# TC37X register map
File version: 1.0.0
CPU: CM4 r0p1, little endian, MPU, FPU, VTOR, 3 interrupt priority bits
Registers are 16-bit, read-write, reset 0x0 unless marked. A register's access mark holds for its fields unless they carry their own. Offsets are from the block's base; [hi:lo] are bit positions; lines under a group give offsets from that group; {n}, {i} and the like mark numbered series.

## PMS — ce_pms
Base 0xF0248000
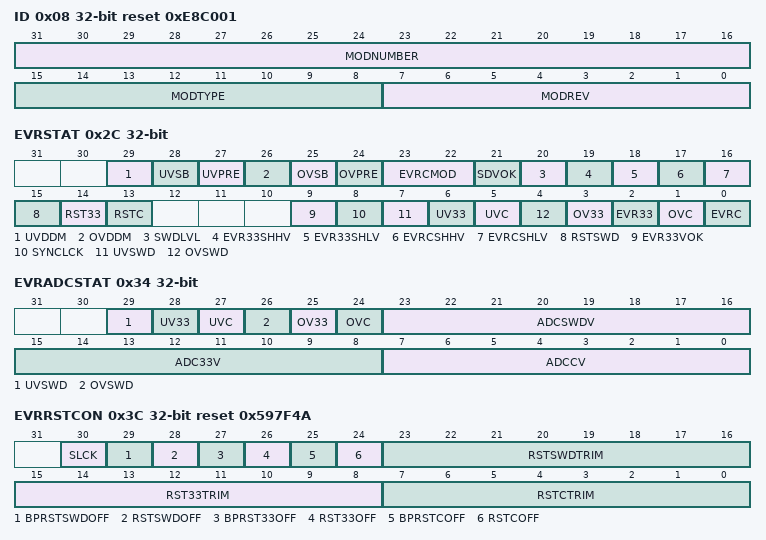
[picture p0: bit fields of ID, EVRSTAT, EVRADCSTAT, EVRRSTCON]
0x08 ID 32-bit ro reset 0xE8C001 — Identification Register
  [31:16] MODNUMBER — Module Number - MODNUMBER
  [15:8] MODTYPE — Module Type - MODTYPE
  [7:0] MODREV — Module Revision Number - MODREV
0x2C EVRSTAT 32-bit ro — EVR Status Register
  [29] UVDDM — ADC VDDM Supply Under-voltage event flag - UVDDM
  [28] UVSB — Standby Supply or VEVRSB Under-voltage event flag - UVSB
  [27] UVPRE — Pre Regulator VDDPD Under-voltage event flag - UVPRE
  [26] OVDDM — ADC VDDM Supply Over-voltage event flag - OVDDM
  [25] OVSB — Standby Supply or VEVRSB Over-voltage event flag - OVSB
  [24] OVPRE — Pre Regulator VDDPD Over-voltage event flag - OVPRE
  [23:22] EVRCMOD — EVRC Mode - EVRCMOD
  [21] SDVOK — EVRC Regulator Voltage OK status - SDVOK
  [20] SWDLVL — VEXT External Supply Level Status - SWDLVL
  [19] EVR33SHHV — Short to supply - EVR33SHHV
  [18] EVR33SHLV — Short to ground - EVR33SHLV
  [17] EVRCSHHV — Short to supply - EVRCSHHV
  [16] EVRCSHLV — Short to ground - EVRCSHLV
  [15] RSTSWD — EVR SWD Reset Trigger - RSTSWD
  [14] RST33 — EVR33 Reset Trigger - RST33
  [13] RSTC — EVRC Reset Trigger - RSTC
  [9] EVR33VOK — EVR33 Regulator Voltage OK status - EVR33VOK
  [8] SYNCLCK — EVRC Synchronization Input Locked status(sd_sync_in_locked_o) - SYNCLCK
  [7] UVSWD — VEXT Under-voltage event flag - UVSWD
  [6] UV33 — VDDP3 Under-voltage event flag - UV33
  [5] UVC — VDD Under-voltage event flag - UVC
  [4] OVSWD — VEXT Over-voltage event flag - OVSWD
  [3] OV33 — VDDP3 Over-voltage event flag - OV33
  [2] EVR33 — EVR33 status - EVR33
  [1] OVC — VDD Over-voltage event flag - OVC
  [0] EVRC — EVRC status - EVRC
0x34 EVRADCSTAT 32-bit ro — EVR Primary ADC Status Register
  [29] UVSWD — Supply Watchdog (SWD) or VEXT Under-voltage event flag - UVSWD
  [28] UV33 — EVR33 Regulator or VDDP3 Under-voltage event flag - UV33
  [27] UVC — EVRC Regulator or VDD Under-voltage event flag - UVC
  [26] OVSWD — Supply Watchdog (SWD) or VEXT Over-voltage event flag - OVSWD
  [25] OV33 — EVR33 Regulator or VDDP3 Over-voltage event flag - OV33
  [24] OVC — EVRC Regulator or VDD Over-voltage event flag - OVC
  [23:16] ADCSWDV — ADC VEXT Supply Conversion Result - ADCSWDV
  [15:8] ADC33V — ADC VDDP3 Voltage Conversion Result - ADC33V
  [7:0] ADCCV — ADC VDD Core Voltage Conversion Result - ADCCV
0x3C EVRRSTCON 32-bit reset 0x597F4A — EVR Reset Control Register
  [30] SLCK — HSM Security Lock - SLCK
  [29] BPRSTSWDOFF wo — Bit Protection RSTSWDOFF - BPRSTSWDOFF
  [28] RSTSWDOFF — VEXT Reset Enable - RSTSWDOFF
  [27] BPRST33OFF wo — Bit Protection RST33OFF - BPRST33OFF
  [26] RST33OFF — VDDP3 Reset Enable - RST33OFF
  [25] BPRSTCOFF wo — Bit Protection RSTCOFF - BPRSTCOFF
  [24] RSTCOFF — VDD Reset Enable - RSTCOFF
  [23:16] RSTSWDTRIM — VEXT Supply Reset Trim Value - RSTSWDTRIM
  [15:8] RST33TRIM — VDDP3 Supply Reset Trim Value - RST33TRIM
  [7:0] RSTCTRIM — VDD Supply Reset Trim Value - RSTCTRIM
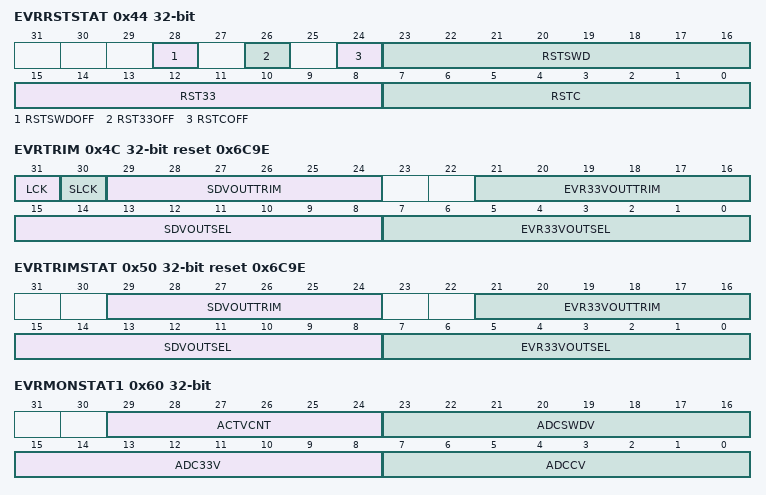
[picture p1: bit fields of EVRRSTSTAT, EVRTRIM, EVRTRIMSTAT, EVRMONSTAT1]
0x44 EVRRSTSTAT 32-bit ro — EVR Reset Status Register
  [28] RSTSWDOFF — EVR SWD Reset Enable - RSTSWDOFF
  [26] RST33OFF — EVR33 Reset Enable Status - RST33OFF
  [24] RSTCOFF — EVRC Reset Enable Status - RSTCOFF
  [23:16] RSTSWD — VEXT Supply Reset Value Status - RSTSWD
  [15:8] RST33 — VDDP3 Supply Reset Value Status - RST33
  [7:0] RSTC — VDD Supply Reset Value Status - RSTC
0x4C EVRTRIM 32-bit reset 0x6C9E — EVR Trim Control Register
  [31] LCK ro — Lock Status - LCK
  [30] SLCK — HSM Security Lock - SLCK
  [29:24] SDVOUTTRIM — EVRC Regulator Output Voltage Trim Value(vtrim_trim_i) - SDVOUTTRIM
  [21:16] EVR33VOUTTRIM — EVR33 Regulator Output Voltage Trim Value - EVR33VOUTTRIM
  [15:8] SDVOUTSEL — EVRC Regulator Output Voltage Target Value - SDVOUTSEL
  [7:0] EVR33VOUTSEL — EVR33 Regulator Output Voltage Target Value - EVR33VOUTSEL
0x50 EVRTRIMSTAT 32-bit ro reset 0x6C9E — EVR Trim Status Register
  [29:24] SDVOUTTRIM — EVRC Regulator Output Voltage Trim Value(vtrim_trim_o) - SDVOUTTRIM
  [21:16] EVR33VOUTTRIM — EVR33 Regulator Output Voltage Trim Value - EVR33VOUTTRIM
  [15:8] SDVOUTSEL — EVRC Regulator Output Voltage Target Value - SDVOUTSEL
  [7:0] EVR33VOUTSEL — EVR33 Regulator Output Voltage Target Value - EVR33VOUTSEL
0x60 EVRMONSTAT1 32-bit ro — EVR Secondary ADC Status Register 1
  [29:24] ACTVCNT — Secondary Monitor Activity Counter - ACTVCNT
  [23:16] ADCSWDV — VEXT Supply Secondary ADC Conversion Result - ADCSWDV
  [15:8] ADC33V — VDDP3 Supply Secondary ADC Conversion Result - ADC33V
  [7:0] ADCCV — VDD Supply Secondary ADC Conversion Result - ADCCV
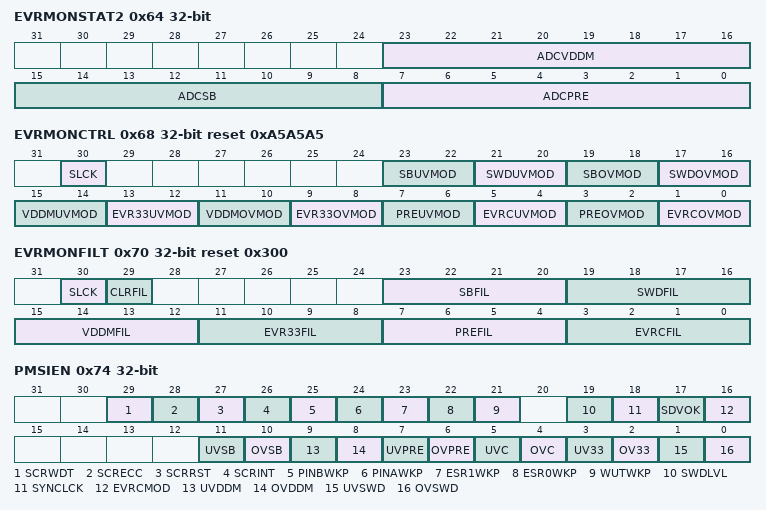
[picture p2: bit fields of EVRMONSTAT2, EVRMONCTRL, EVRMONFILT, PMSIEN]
0x64 EVRMONSTAT2 32-bit ro — EVR Secondary ADC Status Register 2
  [23:16] ADCVDDM — VDDM Supply Secondary ADC Conversion Result - ADCVDDM
  [15:8] ADCSB — VEVRSB Supply Secondary ADC Conversion Result - ADCSB
  [7:0] ADCPRE — VDDPD Supply Secondary ADC Conversion Result - ADCPRE
0x68 EVRMONCTRL 32-bit reset 0xA5A5A5 — EVR Secondary Monitor Control Register
  [30] SLCK — HSM Security Lock - SLCK
  [23:22] SBUVMOD — EVR Standby Supply or VEVRSB Under-voltage monitoring mode - SBUVMOD
  [21:20] SWDUVMOD — VEXT Under-voltage monitoring mode - SWDUVMOD
  [19:18] SBOVMOD — EVR Standby Supply or VEVRSB Over-voltage monitoring mode - SBOVMOD
  [17:16] SWDOVMOD — VEXT Over-voltage monitoring mode - SWDOVMOD
  [15:14] VDDMUVMOD — VDDM ADC Supply Under-voltage monitoring mode - VDDMUVMOD
  [13:12] EVR33UVMOD — VDDP3 Supply Under-voltage monitoring mode - EVR33UVMOD
  [11:10] VDDMOVMOD — VDDM ADC Supply Over-voltage monitoring mode - VDDMOVMOD
  [9:8] EVR33OVMOD — VDDP3 Supply Over-voltage monitoring mode - EVR33OVMOD
  [7:6] PREUVMOD — EVRPR or VDDPD Under-voltage monitoring mode - PREUVMOD
  [5:4] EVRCUVMOD — VDD Under-voltage monitoring mode - EVRCUVMOD
  [3:2] PREOVMOD — EVRPR or VDDPD Over-voltage monitoring mode - PREOVMOD
  [1:0] EVRCOVMOD — VDD Over-voltage monitoring mode - EVRCOVMOD
0x70 EVRMONFILT 32-bit reset 0x300 — EVR Secondary Monitor Filter Register
  [30] SLCK — HSM Security Lock - SLCK
  [29] CLRFIL — Clear all Spike Filters - CLRFIL
  [23:20] SBFIL — VEVRSB Secondary ADC Supply Filter - SBFIL
  [19:16] SWDFIL — VEXT Secondary ADC Supply Filter - SWDFIL
  [15:12] VDDMFIL — VDDM Secondary ADC Supply Filter - VDDMFIL
  [11:8] EVR33FIL — VDDP3 Secondary ADC Supply Filter - EVR33FIL
  [7:4] PREFIL — VDDPD Secondary ADC Supply Filter - PREFIL
  [3:0] EVRCFIL — VDD Secondary ADC Supply Filter - EVRCFIL
0x74 PMSIEN 32-bit — PMS Interrupt Enable Register
  [29] SCRWDT — SCRWDT Interrupt enable - SCRWDT
  [28] SCRECC — SCRECC Interrupt enable - SCRECC
  [27] SCRRST — SCRRST Interrupt enable - SCRRST
  [26] SCRINT — SCRINT Interrupt enable - SCRINT
  [25] PINBWKP — PINBWKP Interrupt enable - PINBWKP
  [24] PINAWKP — PINAWKP Interrupt enable - PINAWKP
  [23] ESR1WKP — ESR1WKP Interrupt enable - ESR1WKP
  [22] ESR0WKP — ESR0WKP Interrupt enable - ESR0WKP
  [21] WUTWKP — WUTWKP Interrupt enable - WUTWKP
  [19] SWDLVL — SWDLVL Interrupt enable - SWDLVL
  [18] SYNCLCK — SD SYNCLCK Interrupt enable - SYNCLCK
  [17] SDVOK — SDVOK Interrupt enable - SDVOK
  [16] EVRCMOD — EVRCMOD Interrupt enable - EVRCMOD
  [11] UVSB — UVSB Interrupt enable - UVSB
  [10] OVSB — OVSB Interrupt enable - OVSB
  [9] UVDDM — UVDDM Interrupt enable - UVDDM
  [8] OVDDM — OVDDM Interrupt enable - OVDDM
  [7] UVPRE — UVPRE Interrupt enable - UVPRE
  [6] OVPRE — OVPRE Interrupt enable - OVPRE
  [5] UVC — UVC Interrupt enable - UVC
  [4] OVC — OVC Interrupt enable - OVC
  [3] UV33 — UV33 Interrupt enable - UV33
  [2] OV33 — OV33 Interrupt enable - OV33
  [1] UVSWD — UVSWD Interrupt enable - UVSWD
  [0] OVSWD — OVSWD Interrupt enable - OVSWD
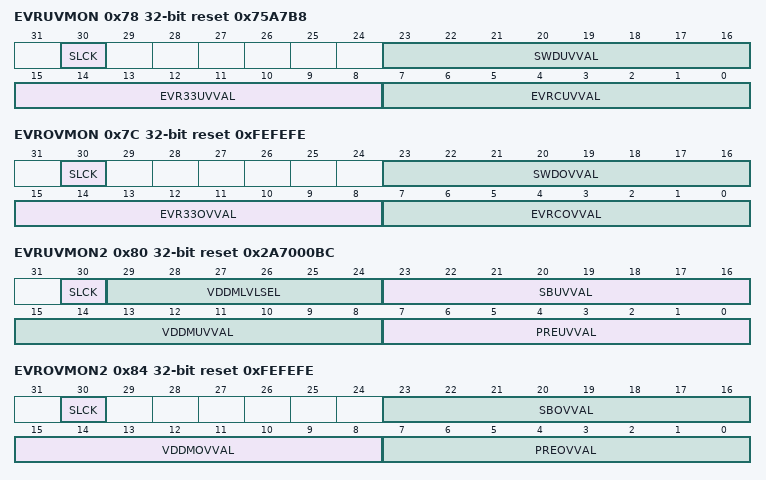
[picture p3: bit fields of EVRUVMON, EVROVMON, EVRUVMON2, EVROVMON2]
0x78 EVRUVMON 32-bit reset 0x75A7B8 — EVR Secondary Under-voltage Monitor Register
  [30] SLCK — HSM Security Lock - SLCK
  [23:16] SWDUVVAL — VEXT Supply Secondary Monitor Under-voltage threshold - SWDUVVAL
  [15:8] EVR33UVVAL — VDDP3 Supply Secondary Monitor Under-voltage threshold - EVR33UVVAL
  [7:0] EVRCUVVAL — VDD Supply Secondary Monitor Under-voltage threshold - EVRCUVVAL
0x7C EVROVMON 32-bit reset 0xFEFEFE — EVR Secondary Over-voltage Monitor Register
  [30] SLCK — HSM Security Lock - SLCK
  [23:16] SWDOVVAL — VEXT Supply Secondary Monitor Over-voltage threshold - SWDOVVAL
  [15:8] EVR33OVVAL — VDDP3 Supply Secondary Monitor Over-voltage threshold - EVR33OVVAL
  [7:0] EVRCOVVAL — VDD Supply Secondary Monitor Over-voltage threshold - EVRCOVVAL
0x80 EVRUVMON2 32-bit reset 0x2A7000BC — EVR Secondary Under-voltage Monitor Register 2
  [30] SLCK — HSM Security Lock - SLCK
  [29:24] VDDMLVLSEL — VDDM Level Select - VDDMLVLSEL
  [23:16] SBUVVAL — VEVRSB Supply Secondary Monitor Under-voltage threshold - SBUVVAL
  [15:8] VDDMUVVAL — VDDM Supply Secondary Monitor Under-voltage threshold - VDDMUVVAL
  [7:0] PREUVVAL — VDDPD Supply Secondary Monitor Under-voltage threshold - PREUVVAL
0x84 EVROVMON2 32-bit reset 0xFEFEFE — EVR Secondary Over-voltage Monitor Register 2
  [30] SLCK — HSM Security Lock - SLCK
  [23:16] SBOVVAL — VEVRSB Supply Secondary Monitor Over-voltage threshold - SBOVVAL
  [15:8] VDDMOVVAL — VDDM Supply Secondary Monitor Over-voltage threshold - VDDMOVVAL
  [7:0] PREOVVAL — VDDPD Supply Secondary Monitor Over-voltage threshold - PREOVVAL
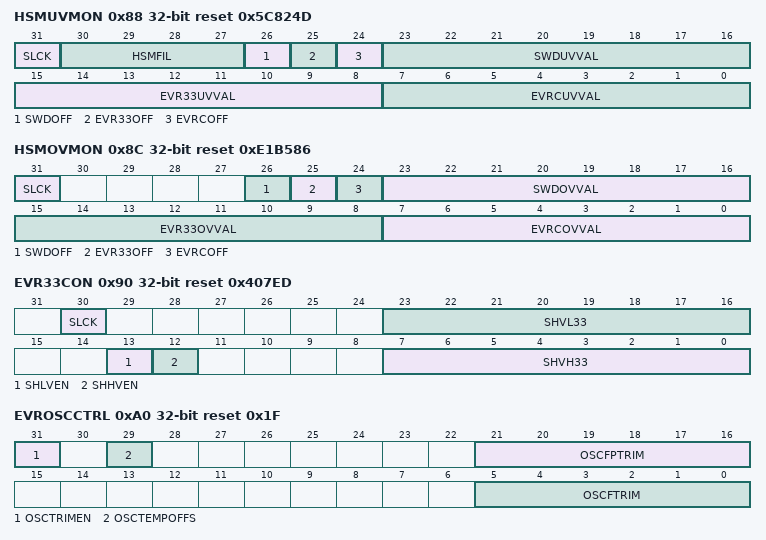
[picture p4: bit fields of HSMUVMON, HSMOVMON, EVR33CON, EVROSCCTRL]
0x88 HSMUVMON 32-bit reset 0x5C824D — EVR Primary HSM Under-voltage Monitor Register
  [31] SLCK — HSM Security Lock - SLCK
  [30:27] HSMFIL — HSM Voltage Filter - HSMFIL
  [26] SWDOFF — VEXT Primary Monitor UV Alarm Disable - SWDOFF
  [25] EVR33OFF — VDDP3 Primary Monitor UV Alarm Disable - EVR33OFF
  [24] EVRCOFF — VDD Primary Monitor UV Alarm Disable - EVRCOFF
  [23:16] SWDUVVAL — VEXT Supply Primary Monitor Alarm Under-voltage threshold - SWDUVVAL
  [15:8] EVR33UVVAL — VDDP3 Supply Primary Monitor Alarm Under-voltage threshold - EVR33UVVAL
  [7:0] EVRCUVVAL — VDD Supply Primary Monitor Alarm Under-voltage threshold - EVRCUVVAL
0x8C HSMOVMON 32-bit reset 0xE1B586 — EVR Primary HSM Over-voltage Monitor Register
  [31] SLCK — HSM Security Lock - SLCK
  [26] SWDOFF — VEXT Primary Monitor OV Alarm Disable - SWDOFF
  [25] EVR33OFF — VDDP3 Primary Monitor OV Alarm Disable - EVR33OFF
  [24] EVRCOFF — VDD Primary Monitor OV Alarm Disable - EVRCOFF
  [23:16] SWDOVVAL — VEXT Supply Primary Monitor Alarm Over-voltage threshold - SWDOVVAL
  [15:8] EVR33OVVAL — VDDP3 Supply Primary Monitor Alarm Over-voltage threshold - EVR33OVVAL
  [7:0] EVRCOVVAL — VDD Supply Primary Monitor Alarm Over-voltage threshold - EVRCOVVAL
0x90 EVR33CON 32-bit reset 0x407ED — EVR33 Control Register
  [30] SLCK — HSM Security Lock - SLCK
  [23:16] SHVL33 — Short to Ground Voltage Threshold(x_i) - SHVL33
  [13] SHLVEN — Short to Low Detection Enable - SHLVEN
  [12] SHHVEN — Short to High Detection Enable - SHHVEN
  [7:0] SHVH33 — Short to Supply Voltage Threshold(x_i) - SHVH33
0xA0 EVROSCCTRL 32-bit reset 0x1F — EVR Oscillator Control Register
  [31] OSCTRIMEN — Dynamic Oscillator Trim Enable - OSCTRIMEN
  [29] OSCTEMPOFFS — Oscillator Temperature Offset Coefficient - OSCTEMPOFFS
  [21:16] OSCFPTRIM — OSC Fine Trim Signed Value - OSCFPTRIM
  [5:0] OSCFTRIM — Back-up Clock Fine Trim Value - OSCFTRIM
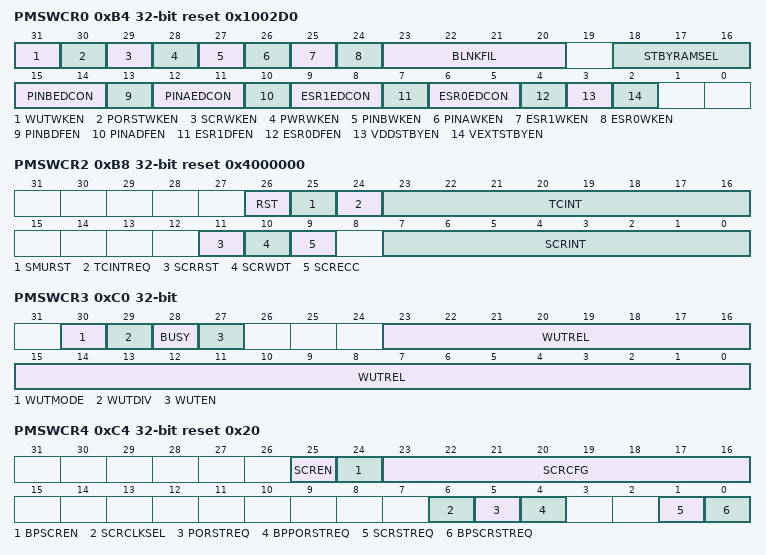
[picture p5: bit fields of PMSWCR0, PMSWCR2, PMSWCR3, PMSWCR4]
0xB4 PMSWCR0 32-bit reset 0x1002D0 — Standby and Wake-up Control Register 0
  [31] WUTWKEN — WUT Wake-up enable from Standby - WUTWKEN
  [30] PORSTWKEN — PORST pin Wake-up enable from Standby - PORSTWKEN
  [29] SCRWKEN — Standby Controller Wake-up enable from Standby - SCRWKEN
  [28] PWRWKEN — Standby Wake-up Enable on VEXT Supply ramp-up - PWRWKEN
  [27] PINBWKEN — Pin B Wake-up enable from Standby - PINBWKEN
  [26] PINAWKEN — Pin A Wake-up enable from Standby - PINAWKEN
  [25] ESR1WKEN — ESR1 Wake-up enable from Standby - ESR1WKEN
  [24] ESR0WKEN — ESR0 Wake-up enable from Standby - ESR0WKEN
  [23:20] BLNKFIL — Blanking Filter delay for Wake-up - BLNKFIL
  [18:16] STBYRAMSEL — Standby RAM supply in Standby Mode - STBYRAMSEL
  [15:14] PINBEDCON — PINB Edge Detection Control - PINBEDCON
  [13] PINBDFEN — PINB Digital Filter Enable - PINBDFEN
  [12:11] PINAEDCON — PINA Edge Detection Control - PINAEDCON
  [10] PINADFEN — PINA Digital Filter Enable - PINADFEN
  [9:8] ESR1EDCON — ESR1 Edge Detection Control - ESR1EDCON
  [7] ESR1DFEN — ESR1 Digital Filter Enable - ESR1DFEN
  [6:5] ESR0EDCON — ESR0 Edge Detection Control - ESR0EDCON
  [4] ESR0DFEN — ESR0 Digital Filter Enable - ESR0DFEN
  [3] VDDSTBYEN — Standby Entry on VDD Supply ramp-down - VDDSTBYEN
  [2] VEXTSTBYEN — Standby Entry on VEXT Supply ramp-down - VEXTSTBYEN
0xB8 PMSWCR2 32-bit reset 0x4000000 — Standby and Wake-up Control Register 2
  [26] RST ro — Application or System Reset indication flag - RST
  [25] SMURST ro — SMU Reset indication flag - SMURST
  [24] TCINTREQ — SW Interrupt request from PMS to Standby Controller. - TCINTREQ
  [23:16] TCINT — Data exchange from PMS main domain to Standby Controller. - TCINT
  [11] SCRRST — SCR Software reset flag - SCRRST
  [10] SCRWDT — SCR Watchdog Timer error / reset flag - SCRWDT
  [9] SCRECC — SCR RAM ECC error / reset flag - SCRECC
  [7:0] SCRINT ro — Data exchange from Standby Controller to PMS main domain. - SCRINT
0xC0 PMSWCR3 32-bit — Standby and Wake-up Control Register 3
  [30] WUTMODE — WUT mode selection - WUTMODE
  [29] WUTDIV — WUT clock divider - WUTDIV
  [28] BUSY ro — Lock Status - LCK
  [27] WUTEN — WUT enable - WUTEN
  [23:0] WUTREL — WUT reload value. - WUTREL
0xC4 PMSWCR4 32-bit reset 0x20 — Standby and Wake-up Control Register 4
  [25] SCREN — Standby Controller Enable request - SCREN
  [24] BPSCREN wo — Standby Controller Reset request enable - BPSCREN
  [23:16] SCRCFG — Hardware configuration of the 8 bit SCR controller. - SCRCFG
  [6] SCRCLKSEL — Default Clock selection on Standby Mode Entry - SCRCLKSEL
  [5] PORSTREQ — SCR Reset behavior on warm PORST in Normal RUN / SLEEP mode - PORSTREQ
  [4] BPPORSTREQ wo — Bit Protection for PORSTREQ - PORSTEN
  [1] SCRSTREQ — Standby Controller Reset request - SCRSTREQ
  [0] BPSCRSTREQ wo — Standby Controller Reset request enable - SCRSTEN
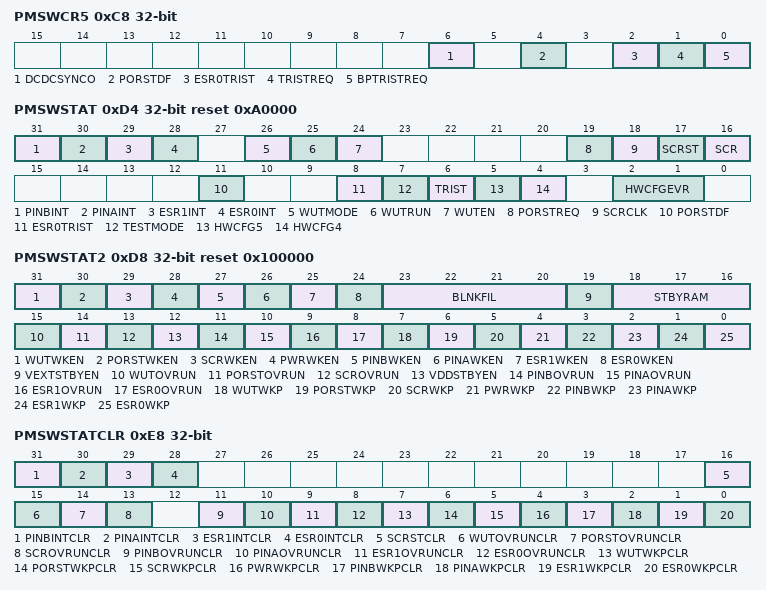
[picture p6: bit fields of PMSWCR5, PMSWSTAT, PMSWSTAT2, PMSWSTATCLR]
0xC8 PMSWCR5 32-bit — Standby and Wake-up Control Register 5
  [6] DCDCSYNCO — DC-DC Synchronisation Output
  [4] PORSTDF — PORST Digital Filter enable - PORSTDF
  [2] ESR0TRIST — ESR0 Tristate enable - ESR0TRIST
  [1] TRISTREQ — Tristate enable - TRISTREQ
  [0] BPTRISTREQ wo — Bit protection for Tristate request bit (TRISTREQ) - BPTRISTREQ
0xD4 PMSWSTAT 32-bit ro reset 0xA0000 — Standby and Wake-up Status Register
  [31] PINBINT — Pin B Interrupt flag - PINBINT
  [30] PINAINT — Pin A Interrupt flag - PINAINT
  [29] ESR1INT — ESR1 Interrupt flag - ESR1INT
  [28] ESR0INT — ESR0 Interrupt flag - ESR0INT
  [26] WUTMODE — WUT Mode status - WUTMODE
  [25] WUTRUN — WUT Run status - WUTRUN
  [24] WUTEN — WUT Enable status - WUTEN
  [19] PORSTREQ — Standby Controller Reset on warm PORST - PORSTREQ
  [18] SCRCLK — Current Clock configuration for SCR before Standby Mode Entry - SCRCLK
  [17] SCRST — Standby Controller Reset Indication flag - SCRST
  [16] SCR — Standby Controller status - SCR
  [11] PORSTDF — PORST Digital Filter status - PORSTDF
  [8] ESR0TRIST — ESR0 pin status during Standby - ESR0TRIST
  [7] TESTMODE — TESTMODE Pin status - TESTMODE
  [6] TRIST — Pad Tristate / Pull-up status - TRIST
  [5] HWCFG5 — Hardware Configuration Pin 5 status - HWCFG5
  [4] HWCFG4 — Hardware Configuration Pin 4 status - HWCFG4
  [2:1] HWCFGEVR — EVR Hardware Configuration status - HWCFGEVR
0xD8 PMSWSTAT2 32-bit ro reset 0x100000 — Standby and Wake-up Status Register 2
  [31] WUTWKEN — WUT Wake-up enable status - WUTWKEN
  [30] PORSTWKEN — PORST pin Wake-up enable status from Standby - PORSTWKEN
  [29] SCRWKEN — Standby Controller Wake-up Enable status - SCRWKEN
  [28] PWRWKEN — Standby Wake-up Enable status on VEXT Supply ramp-up - PWRWKEN
  [27] PINBWKEN — Pin B Wake-up enable status - PINBWKEN
  [26] PINAWKEN — Pin A Wake-up enable status - PINAWKEN
  [25] ESR1WKEN — ESR1 Wake-up enable status - ESR1WKEN
  [24] ESR0WKEN — ESR0 Wake-up enable status - ESR0WKEN
  [23:20] BLNKFIL — Blanking Filter Delay for VEXT Supply Wake-up - BLNKFIL
  [19] VEXTSTBYEN — Standby Entry Enable status on VEXT Supply ramp-down - VEXTSTBYWKEN
  [18:16] STBYRAM — Standby RAM Supply status - STBYRAM
  [15] WUTOVRUN — WUT Overrun status flag - WUTOVRUN
  [14] PORSTOVRUN — PORST Overrun status flag - PORSTOVRUN
  [13] SCROVRUN — SCR Overrun status flag - SCROVRUN
  [12] VDDSTBYEN — Standby Entry Enable status on VDD Supply ramp-down - VDDSTBYWKEN
  [11] PINBOVRUN — Pin B Overrun status flag - PINBOVRUN
  [10] PINAOVRUN — Pin A Overrun status flag - PINAOVRUN
  [9] ESR1OVRUN — ESR1 Overrun status flag - ESR1OVRUN
  [8] ESR0OVRUN — ESR0 Overrun status flag - ESR0OVRUN
  [7] WUTWKP — WUT Wake-up flag - WUTWKP
  [6] PORSTWKP — PORST Wake-up flag - PORSTWKP
  [5] SCRWKP — SCR Wake-up flag - SCRWKP
  [4] PWRWKP — Wake-up event on VEXT Supply ramp-up - PWRWKP
  [3] PINBWKP — Pin B Wake-up flag - PINBWKP
  [2] PINAWKP — Pin Wake-up flag - PINAWKP
  [1] ESR1WKP — ESR1 Wake-up flag - ESR1WKP
  [0] ESR0WKP — ESR0 Wake-up flag - ESR0WKP
0xDC PMSWUTCNT 32-bit ro — Standby WUT Counter Register
  [23:0] WUTCNT — WUT counter value. - WUTCNT
0xE8 PMSWSTATCLR 32-bit wo — Standby and Wake-up Status Clear Register
  [31] PINBINTCLR — PINB Interrupt indication flag clear - PINBINTCLR
  [30] PINAINTCLR — PINA Interrupt indication flag clear - PINAINTCLR
  [29] ESR1INTCLR — ESR1 Interrupt indication flag clear - ESR1INTCLR
  [28] ESR0INTCLR — ESR0 Interrupt indication flag clear - ESR0INTCLR
  [16] SCRSTCLR — Standby controller SCRST indication flag clear - SCRSTCLR
  [15] WUTOVRUNCLR — WUT Overrun status indication flag clear - WUTOVRUNCLR
  [14] PORSTOVRUNCLR — PORST Overrun status indication flag clear - PORSTOVRUNCLR
  [13] SCROVRUNCLR — SCR Overrun status indication flag clear - SCROVRUNCLR
  [11] PINBOVRUNCLR — PINB Overrun status indication flag clear - PINBOVRUNCLR
  [10] PINAOVRUNCLR — PINA Overrun status indication flag clear - PINAOVRUNCLR
  [9] ESR1OVRUNCLR — ESR1 Overrun status indication flag clear - ESR1OVRUNCLR
  [8] ESR0OVRUNCLR — ESR0 Overrun status indication flag clear - ESR0OVRUNCLR
  [7] WUTWKPCLR — WUT Wake-up indication flag clear - WUTWKPCLR
  [6] PORSTWKPCLR — PORST Wake-up indication flag clear - PORSTWKPCLR
  [5] SCRWKPCLR — SCR Wake-up indication flag clear - SCRWKPCLR
  [4] PWRWKPCLR — PWRWKP Wake-up indication flag clear - PWRWKPCLR
  [3] PINBWKPCLR — PINB Wake-up indication flag clear - PINBWKPCLR
  [2] PINAWKPCLR — PINA Wake-up indication flag clear - PINAWKPCLR
  [1] ESR1WKPCLR — ESR1 Wake-up indication flag clear - ESR1WKPCLR
  [0] ESR0WKPCLR — ESR0 Wake-up indication flag clear - ESR0WKPCLR
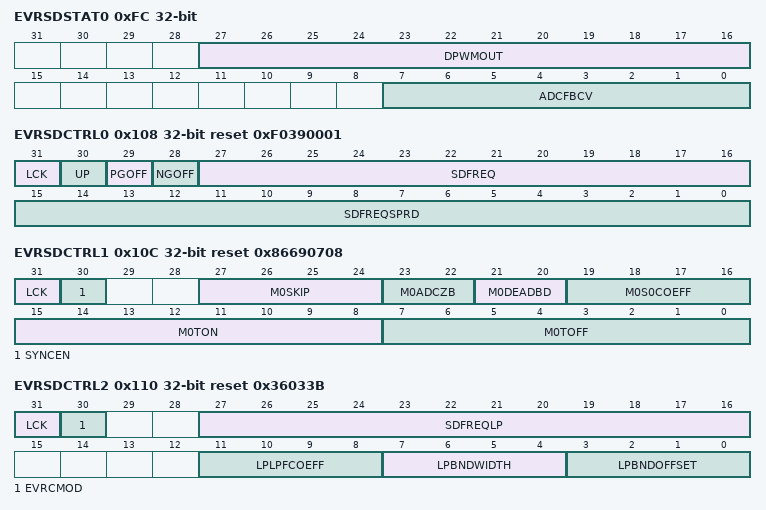
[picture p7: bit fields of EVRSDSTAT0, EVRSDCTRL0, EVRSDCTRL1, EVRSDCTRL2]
0xFC EVRSDSTAT0 32-bit ro — EVR SD Status Register 0
  [27:16] DPWMOUT — DPWM Control Output Status - DPWMOUT
  [7:0] ADCFBCV — Step Down Converter Core Voltage Feedback ADC Conversion Result - ADCFBCV
0x108 EVRSDCTRL0 32-bit reset 0xF0390001 — EVRC SD Control Register 0
  [31] LCK ro — Lock Status - LCK
  [30] UP — Update request for SMPS register values - UP
  [29] PGOFF — PMOS level during OFF state(drvslo_pgoff_i) - PGOFF
  [28] NGOFF — NMOS level during OFF state(drvslo_ngoff_i) - NGOFF
  [27:16] SDFREQ — Regulator Switching Frequency or Over-sampling Factor(m0osfl_fact_i+m0osfh_fact_i) - SDFREQ
  [15:0] SDFREQSPRD — Frequency Spread Threshold(freqsp_coeff_i) - SDFREQSPRD
0x10C EVRSDCTRL1 32-bit reset 0x86690708 — EVRC SD Control Register 1
  [31] LCK ro — Lock Status - LCK
  [30] SYNCEN — EVRC Synchronization input enable(synci0_en_i) - SYNCEN
  [27:24] M0SKIP — Skip Pulse Threshold(m0skip_thres_i) - M0SKIP
  [23:22] M0ADCZB — ADC Zero Bin(m0fcfg_adczb_i) - M0ADCZB
  [21:20] M0DEADBD — Dead Band(m0s0_deadbd_i) - M0DEADBD
  [19:16] M0S0COEFF — S0 coefficient(m0s0_coeff_i) - M0S0COEFF
  [15:8] M0TON — Minimum On Time(m0ton_minton_i) - M0TON
  [7:0] M0TOFF — Minimum Off Time(m0toff_mintof_i) - M0TOFF
0x110 EVRSDCTRL2 32-bit reset 0x36033B — EVRC SD Control Register 2
  [31] LCK ro — Lock Status - LCK
  [30] EVRCMOD — LPM or PWM EVRC Mode Activation - EVRCMOD
  [27:16] SDFREQLP — Regulator Over-sampling Factor(m1osfl_fact_i+m1osfh_fact_i) - SDFREQLP
  [11:8] LPLPFCOEFF — Low Pass Filter Coefficient(lplpf_coeff_i) - LPLPFCOEFF
  [7:4] LPBNDWIDTH — Low Power Mode Hysteresis Band Width(lpbnd_width_i) - LPBNDWIDTH
  [3:0] LPBNDOFFSET — Low Power Mode Hysteresis OFFSET(lpbnd_offset_i) - LPBNDOFFSET
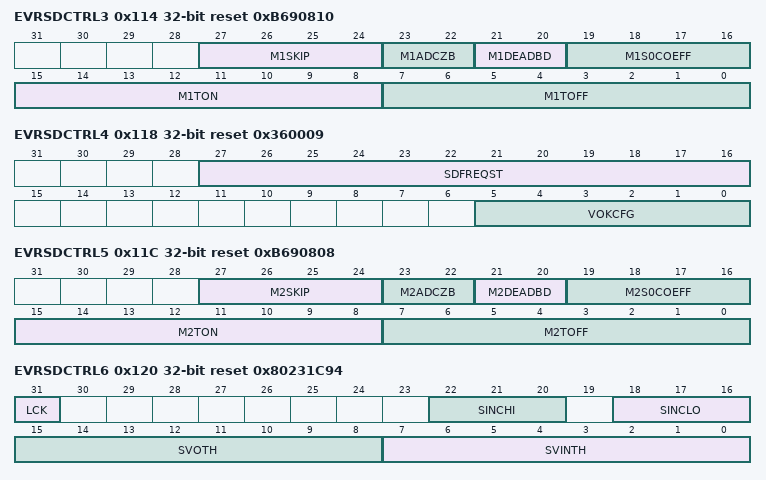
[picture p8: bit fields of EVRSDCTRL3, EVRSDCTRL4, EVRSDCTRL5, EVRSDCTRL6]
0x114 EVRSDCTRL3 32-bit reset 0xB690810 — EVRC SD Control Register 3
  [27:24] M1SKIP — Skip Pulse Threshold(m1skip_thres_i) - M1SKIP
  [23:22] M1ADCZB — ADC Zero Bin(m1fcfg_adczb_i) - M1ADCZB
  [21:20] M1DEADBD — Dead Band(m1s0_deadbd_i) - M1DEADBD
  [19:16] M1S0COEFF — S0 coefficient(m1s0_coeff_i) - M1S0COEFF
  [15:8] M1TON — Minimum On Time(m1ton_minton_i) - M1TON
  [7:0] M1TOFF — Minimum Off Time(m1toff_mintof_i) - M1TOFF
0x118 EVRSDCTRL4 32-bit reset 0x360009 — EVRC SD Control Register 4
  [27:16] SDFREQST — Regulator Switching Frequency or Over-sampling Factor(m2osfl_fact_i+m2osfh_fact_i) - SDFREQST
  [5:0] VOKCFG — Voltage OK Circuit Configuration(vokcfg_config_i) - VOKCFG
0x11C EVRSDCTRL5 32-bit reset 0xB690808 — EVRC SD Control Register 5
  [27:24] M2SKIP — Skip Pulse Threshold(m2skip_thres_i) - M2SKIP
  [23:22] M2ADCZB — ADC Zero Bin(m2fcfg_adczb_i) - M2ADCZB
  [21:20] M2DEADBD — Dead Band(m2s0_deadbd_i) - M2DEADBD
  [19:16] M2S0COEFF — S0 coefficient(m2s0_coeff_i) - M2S0COEFF
  [15:8] M2TON — Minimum On Time(m2ton_minton_i) - M2TON
  [7:0] M2TOFF — Minimum Off Time(m2toff_mintof_i) - M2TOFF
0x120 EVRSDCTRL6 32-bit reset 0x80231C94 — EVRC SD Control Register 6
  [31] LCK ro — Lock Status - LCK
  [22:20] SINCHI — Increment for high input voltage.(sinc_sinchi_i) - SINCHI
  [18:16] SINCLO — Increment for low input voltage.(sinc_sinclo_i) - SINCLO
  [15:8] SVOTH — Vout threshold to switch from open loop start-up to closed loop mode.(svoth_thres_i) - SVOTH
  [7:0] SVINTH — Vin threshold to switch between SINCLO or SINCHI.(svinth_thres_i) - SVINTH
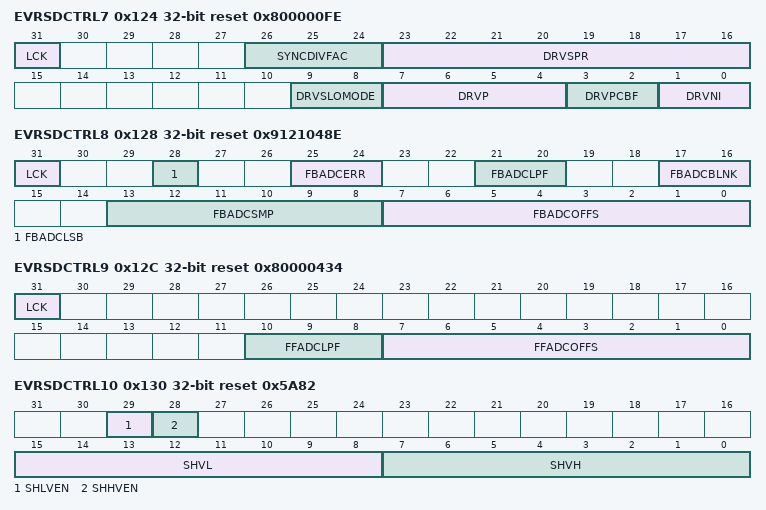
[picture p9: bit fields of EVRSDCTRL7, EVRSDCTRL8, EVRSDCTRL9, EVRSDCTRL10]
0x124 EVRSDCTRL7 32-bit reset 0x800000FE — EVRC SD Control Register 7
  [31] LCK ro — Lock Status - LCK
  [26:24] SYNCDIVFAC — Switching frequency division factor for external synchronisation(synco_divfac_i) - SYNCDIVFAC
  [23:16] DRVSPR — Spare bits(drvspr_x_i) - DRVSPR
  [9:8] DRVSLOMODE — Switching Configuration(drvslo_mode_i) - DRVSLOMODE
  [7:4] DRVP — P-Driver Current(drvp_strgth_i) - DRVP
  [3:2] DRVPCBF — P-Driver Current Boost Factor(drvp_strgth_i) - DRVPCBF
  [1:0] DRVNI — Selection of N-driver current - DRVNI
0x128 EVRSDCTRL8 32-bit reset 0x9121048E — EVRC SD Control Register 8
  [31] LCK ro — Lock Status - LCK
  [28] FBADCLSB — FB ADC LSB for Error Computation(fbadc3_lsb_i) - FBADCLSB
  [25:24] FBADCERR — FB ADC Error LPF Coefficient(fbadc3_lpferr_i) - FBADCERR
  [21:20] FBADCLPF — FB ADC Counter LPF Coefficient(fbadc0_lpfcnt_i) - FBADCLPF
  [17:16] FBADCBLNK — FB ADC Blanked Samples Number(fbadc0_blank_i) - FBADCBLNK
  [13:8] FBADCSMP — FB ADC Sampling period(fbadc1_smpthr_i) - FBADCSMP
  [7:0] FBADCOFFS — Feedback Converted Counter Value Offset(fbadc2_offset_i) - FBADCOFFS
0x12C EVRSDCTRL9 32-bit reset 0x80000434 — EVRC SD Control Register 9
  [31] LCK ro — Lock Status - LCK
  [10:8] FFADCLPF — FF ADC Counter LPF Coefficient(ffadc0_lpfcnt_i) - FFADCLPF
  [7:0] FFADCOFFS — Feed Forward Converted Counter Value Offset(ffadc1_offset_i) - FFADCOFFS
0x130 EVRSDCTRL10 32-bit reset 0x5A82 — EVRC SD Control Register 10
  [29] SHLVEN — Short to Low Detection Enable(shrtl0_shlven_i) - SHLVEN
  [28] SHHVEN — Short to High Detection Enable(shrth0_shhven_i) - SHHVEN
  [15:8] SHVL — Short to Low Voltage Threshold(shrtl1_shvl_i) - SHVL
  [7:0] SHVH — Short to High Voltage Threshold(shrth1_shvh_i) - SHVH
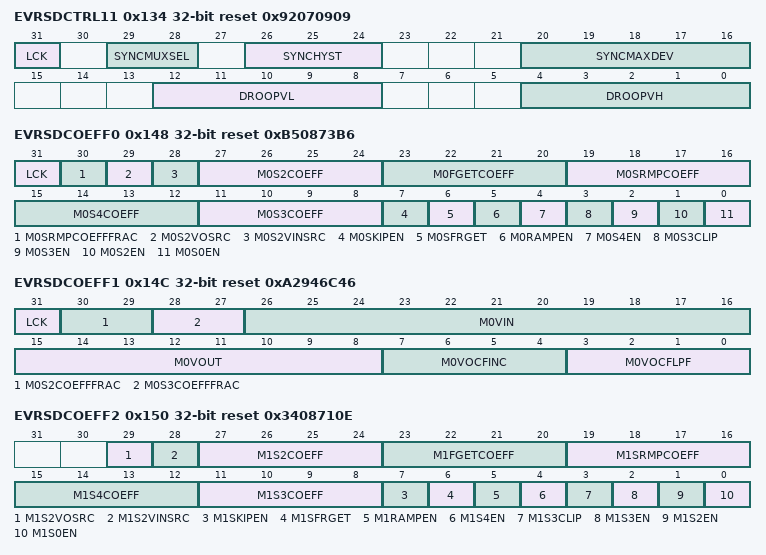
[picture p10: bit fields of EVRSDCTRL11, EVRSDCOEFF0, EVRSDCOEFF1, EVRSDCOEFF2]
0x134 EVRSDCTRL11 32-bit reset 0x92070909 — EVRC SD Control Register 11
  [31] LCK ro — Lock Status - LCK
  [29:28] SYNCMUXSEL — Synchronisation Input Multiplexer - SYNCMUXSEL
  [26:24] SYNCHYST — Lock Unlock Hysteresis Window(synci0_hyst_i) - SYNCHYST
  [20:16] SYNCMAXDEV — Maximum Deviation of the Synchronization Input Frequency(synci1_maxdev_i) - SYNCMAXDEV
  [12:8] DROOPVL — Low VDD Limit for Droop request(droopvl_thres_i) - DROOPVL
  [4:0] DROOPVH — High VDD Limit for Droop request(droopvh_thres_i) - DROOPVH
0x148 EVRSDCOEFF0 32-bit reset 0xB50873B6 — EVRC SD Coefficient Register 0
  [31] LCK ro — Lock Status - LCK
  [30] M0SRMPCOEFFFRAC — S Ramp Fractional Coefficient
  [29] M0S2VOSRC — S2 Vout Source(m0s2_vosrc_i) - M0S2VOSRC
  [28] M0S2VINSRC — S2 Vin Source(m0s2_vinsrc_i) - M0S2VINSRC
  [27:24] M0S2COEFF — S2 Coefficient(m0s2_coeff_i) - M0S2COEFF
  [23:20] M0FGETCOEFF — S2 Forgetting Factor(m0fget_coeff_i) - M0FGETCOEFF
  [19:16] M0SRMPCOEFF — S Ramp Coefficient(m0srmp_coeff_i) - M0SRMPCOEFF
  [15:12] M0S4COEFF — S4 Coefficient(m0s4_coeff_i) - M0S4COEFF
  [11:8] M0S3COEFF — S3 Coefficient(m0s3_coeff_i) - M0S3COEFF
  [7] M0SKIPEN — Skip Enable(m0en_skipen_i) - M0SKIPEN
  [6] M0SFRGET — SFRGET(m0en_sfrget_i) - M0SFRGET
  [5] M0RAMPEN — Ramp Enable(m0en_rampen_i) - M0RAMPEN
  [4] M0S4EN — S4 Enable(m0en_s4en_i) - M0S4EN
  [3] M0S3CLIP — S3 Clip(m0en_s3clip_i) - M0S3CLIP
  [2] M0S3EN — S3 Enable(m0en_s3en_i) - M0S3EN
  [1] M0S2EN — S2 Enable(m0en_s2en_i) - M0S2EN
  [0] M0S0EN — S0 Enable(m0en_s0en_i) - M0S0EN
0x14C EVRSDCOEFF1 32-bit reset 0xA2946C46 — EVRC SD Coefficient Register 1
  [31] LCK ro — Lock Status - LCK
  [30:29] M0S2COEFFFRAC — S2 Fractional Coefficient
  [28:27] M0S3COEFFFRAC — S3 Fractional Coefficient
  [26:16] M0VIN — Digital representation of the input voltage(m0vinh_vin_i+m0vinl_vin_i)) - M0VIN
  [15:8] M0VOUT — Digital representation of the target voltage(m0vo_lb_i) - M0VOUT
  [7:4] M0VOCFINC — Output Voltage Ramp Coefficient(m0vocf_inc_i) - M0VOCFINC
  [3:0] M0VOCFLPF — LPF Coefficient(m0vocf_lpf_i) - M0VOCFLPF
0x150 EVRSDCOEFF2 32-bit reset 0x3408710E — EVRC SD Coefficient Register 2
  [29] M1S2VOSRC — S2 Vout Source(m1s2_vosrc_i) - M1S2VOSRC
  [28] M1S2VINSRC — S2 Vin Source(m1s2_vinsrc_i) - M1S2VINSRC
  [27:24] M1S2COEFF — S2 Coefficient(m1s2_coeff_i) - M1S2COEFF
  [23:20] M1FGETCOEFF — S2 Forgetting Factor(m1fget_coeff_i) - M1FGETCOEFF
  [19:16] M1SRMPCOEFF — S Ramp Coefficient(m1srmp_coeff_i) - M1SRMPCOEFF
  [15:12] M1S4COEFF — S4 Coefficient(m1s4_coeff_i) - M1S4COEFF
  [11:8] M1S3COEFF — S3 Coefficient(m1s3_coeff_i) - M1S3COEFF
  [7] M1SKIPEN — Skip Enable(m1en_skipen_i) - M1SKIPEN
  [6] M1SFRGET — SFRGET(m1en_sfrget_i) - M1SFRGET
  [5] M1RAMPEN — Ramp Enable(m1en_rampen_i) - M1RAMPEN
  [4] M1S4EN — S4 Enable(m1en_s4en_i) - M1S4EN
  [3] M1S3CLIP — S3 Clip(m1en_s3clip_i) - M1S3CLIP
  [2] M1S3EN — S3 Enable(m1en_s3en_i) - M1S3EN
  [1] M1S2EN — S2 Enable(m1en_s2en_i) - M1S2EN
  [0] M1S0EN — S0 Enable(m1en_s0en_i) - M1S0EN
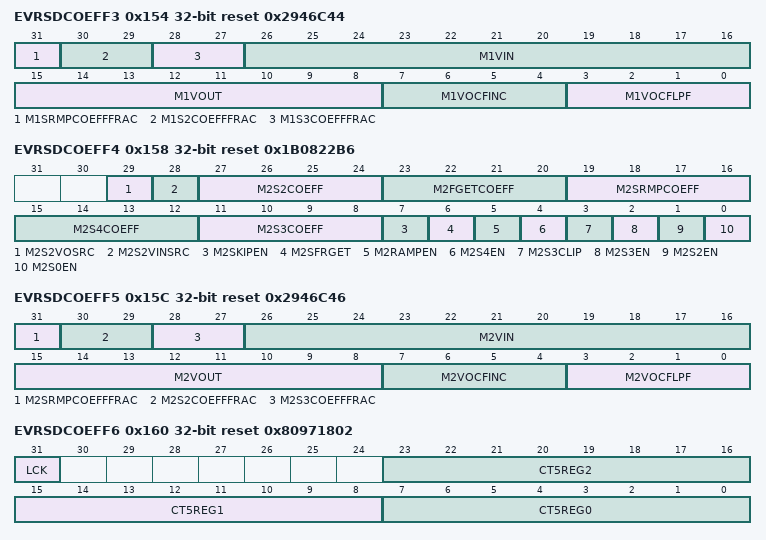
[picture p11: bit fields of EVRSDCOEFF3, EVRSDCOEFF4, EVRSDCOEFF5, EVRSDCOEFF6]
0x154 EVRSDCOEFF3 32-bit reset 0x2946C44 — EVRC SD Coefficient Register 3
  [31] M1SRMPCOEFFFRAC — S Ramp Fractional Coefficient
  [30:29] M1S2COEFFFRAC — S2 Fractional Coefficient
  [28:27] M1S3COEFFFRAC — S3 Fractional Coefficient
  [26:16] M1VIN — Digital representation of the input voltage(m1vinh_vin_i+m1vinl_vin_i) - M1VIN
  [15:8] M1VOUT — Digital representation of the target voltage(m1vo_lb_i) - M1VOUT
  [7:4] M1VOCFINC — Output Voltage Ramp Coefficient(m1vocf_inc_i) - M1VOCFINC
  [3:0] M1VOCFLPF — LPF Coefficient(m1vocf_lpf_i) - M1VOCFLPF
0x158 EVRSDCOEFF4 32-bit reset 0x1B0822B6 — EVRC SD Coefficient Register 4
  [29] M2S2VOSRC — S2 Vout Source(m2s2_vosrc_i) - M2S2VOSRC
  [28] M2S2VINSRC — S2 Vin Source(m2s2_vinsrc_i) - M2S2VINSRC
  [27:24] M2S2COEFF — S2 Coefficient(m2s2_coeff_i) - M2S2COEFF
  [23:20] M2FGETCOEFF — S2 Forgetting Factor(m2fget_coeff_i) - M2FGETCOEFF
  [19:16] M2SRMPCOEFF — S Ramp Coefficient(m2srmp_coeff_i) - M2SRMPCOEFF
  [15:12] M2S4COEFF — S4 Coefficient(m2s4_coeff_i) - M2S4COEFF
  [11:8] M2S3COEFF — S3 Coefficient(m2s3_coeff_i) - M2S3COEFF
  [7] M2SKIPEN — Skip Enable(m2en_skipen_i) - M2SKIPEN
  [6] M2SFRGET — SFRGET(m2en_sfrget_i) - M2SFRGET
  [5] M2RAMPEN — Ramp Enable(m2en_rampen_i) - M2RAMPEN
  [4] M2S4EN — S4 Enable(m2en_s4en_i) - M2S4EN
  [3] M2S3CLIP — S3 Clip(m2en_s3clip_i) - M2S3CLIP
  [2] M2S3EN — S3 Enable(m2en_s3en_i) - M2S3EN
  [1] M2S2EN — S2 Enable(m2en_s2en_i) - M2S2EN
  [0] M2S0EN — S0 Enable(m2en_s0en_i) - M2S0EN
0x15C EVRSDCOEFF5 32-bit reset 0x2946C46 — EVRC SD Coefficient Register 5
  [31] M2SRMPCOEFFFRAC — S Ramp Fractional Coefficient
  [30:29] M2S2COEFFFRAC — S2 Fractional Coefficient
  [28:27] M2S3COEFFFRAC — S3 Fractional Coefficient
  [26:16] M2VIN — Digital representation of the input voltage(m2vinh_vin_i+m2vinl_vin_i) - M2VIN
  [15:8] M2VOUT — Digital representation of the target voltage(m2vo_lb_i) - M2VOUT
  [7:4] M2VOCFINC — Output Voltage Ramp Coefficient(m2vocf_inc_i) - M2VOCFINC
  [3:0] M2VOCFLPF — LPF Coefficient(m2vocf_lpf_i) - M2VOCFLPF
0x160 EVRSDCOEFF6 32-bit reset 0x80971802 — EVRC SD Coefficient Register 6
  [31] LCK ro — Lock Status - LCK
  [23:16] CT5REG2 — Commutation trimming(drv5v2_trim_i) - CT5REG2
  [15:8] CT5REG1 — Commutation trimming(drv5v1_trim_i) - CT5REG1
  [7:0] CT5REG0 — Commutation trimming and Slope Control(drv5v0_trim_i) - CT5REG0
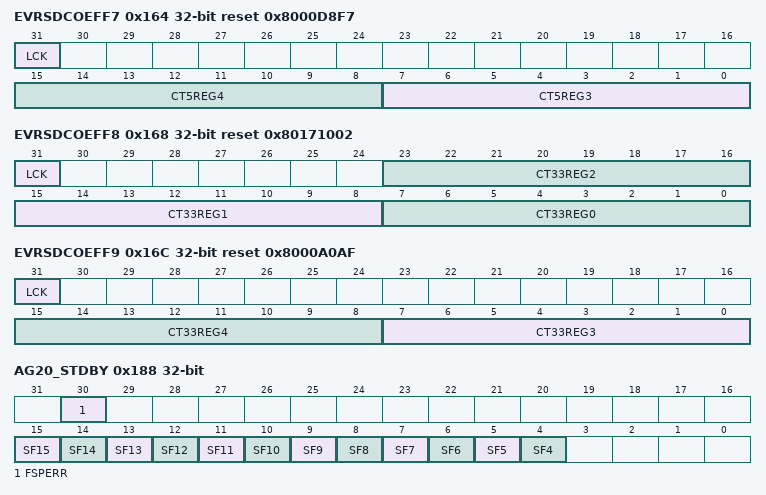
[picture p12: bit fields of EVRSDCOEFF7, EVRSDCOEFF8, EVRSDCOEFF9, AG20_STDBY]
0x164 EVRSDCOEFF7 32-bit reset 0x8000D8F7 — EVRC SD Coefficient Register 7
  [31] LCK ro — Lock Status - LCK
  [15:8] CT5REG4 — Commutation trimming(drv5v4_trim_i) - CT5REG4
  [7:0] CT5REG3 — Commutation trimming(drv5v3_trim_i) - CT5REG3
0x168 EVRSDCOEFF8 32-bit reset 0x80171002 — EVRC SD Coefficient Register 8
  [31] LCK ro — Lock Status - LCK
  [23:16] CT33REG2 — Commutation trimming(drv3v2_trim_i) - CT33REG2
  [15:8] CT33REG1 — Commutation trimming(drv3v1_trim_i) - CT33REG1
  [7:0] CT33REG0 — Commutation trimming(drv3v0_trim_i) - CT33REG0
0x16C EVRSDCOEFF9 32-bit reset 0x8000A0AF — EVRC SD Coefficient Register 9
  [31] LCK ro — Lock Status - LCK
  [15:8] CT33REG4 — Commutation trimming(drv3v4_trim_i) - CT33REG4
  [7:0] CT33REG3 — Commutation trimming(drv3v3_trim_i) - CT33REG3
0x188 AG20_STDBY 32-bit — Alarm Status Register
  [30] FSPERR — Error Pin Fault State Status Bit - FSPERR
  [n] SF{n} (n=4..15) — Status flag for alarm {n} belonging to alarm group i. - SF{n}
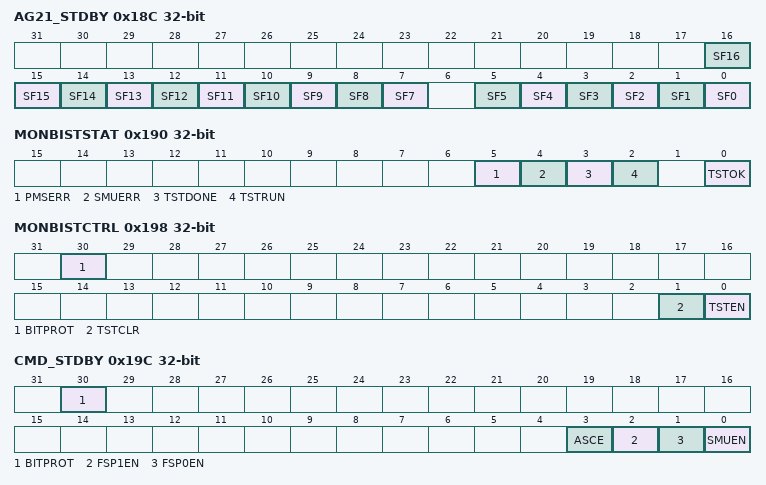
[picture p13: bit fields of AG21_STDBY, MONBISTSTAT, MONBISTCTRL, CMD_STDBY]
0x18C AG21_STDBY 32-bit — Alarm Status Register
  [n] SF{n} (n=7..16) — Status flag for alarm {n} belonging to alarm group i. - SF{n}
  [n] SF{n} (n=0..5) — Status flag for alarm {n} belonging to alarm group i. - SF{n}
0x190 MONBISTSTAT 32-bit ro — SMU_stdby BIST Status Register
  [5] PMSERR — Error found in PMS SARADC by SMU_stdby BIST
  [4] SMUERR — Error found in SMU_stdby found by SMU_stdby BIST
  [3] TSTDONE — SMU_stdby BIST done bit - TSTDONE
  [2] TSTRUN — SMU_stdby BIST run bit - TSTRUN
  [0] TSTOK — SMU_stdby BIST ok bit - TSTOK
0x198 MONBISTCTRL 32-bit — SMU_stdby BIST Control Register
  [30] BITPROT wo — Bit Protection TSTEN - BITPROT
  [1] TSTCLR wo — SMU_stdby BIST flag clear - TSTCLR
  [0] TSTEN — SMU_stdby alarm BIST enable - TSTEN
0x19C CMD_STDBY 32-bit — SMU_stdby Command Register
  [30] BITPROT wo — CMD_STDBY register bits protection
  [3] ASCE — SMU_stdby alarm status clear enable - ASCE
  [2] FSP1EN — SMU_stdby FSP1 Error pin enable - FSP1EN
  [1] FSP0EN — SMU_stdby FSP0 Error pin enable - FSP0EN
  [0] SMUEN — SMU_stdby Module Enable - SMUEN
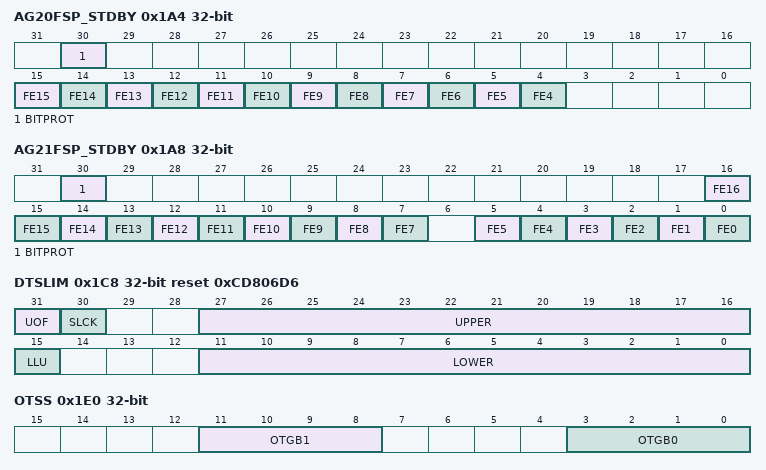
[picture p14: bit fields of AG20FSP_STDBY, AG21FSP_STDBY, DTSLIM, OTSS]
0x1A4 AG20FSP_STDBY 32-bit — SMU_stdby FSP Configuration Register
  [30] BITPROT wo — AG2iFSP_STDBY register bits protection
  [n] FE{n} (n=4..15) — Fault signaling configuration flag for alarm {n} belonging to alarm group i. - FE{n}
0x1A8 AG21FSP_STDBY 32-bit — SMU_stdby FSP Configuration Register
  [30] BITPROT wo — AG2iFSP_STDBY register bits protection
  [n] FE{n} (n=7..16) — Fault signaling configuration flag for alarm {n} belonging to alarm group i. - FE{n}
  [n] FE{n} (n=0..5) — Fault signaling configuration flag for alarm {n} belonging to alarm group i. - FE{n}
0x1C0 DTSSTAT 32-bit ro — Die Temperature Sensor Status Register
  [11:0] RESULT — Result of the DTS Measurement - RESULT
0x1C8 DTSLIM 32-bit reset 0xCD806D6 — Die Temperature Sensor Limit Register
  [31] UOF — Upper Limit Overflow - UOF
  [30] SLCK — HSM Security Lock - SLCK
  [27:16] UPPER — Upper Limit - UPPER
  [15] LLU — Lower Limit Underflow - LLU
  [11:0] LOWER — Lower Limit - LOWER
0x1E0 OTSS 32-bit — OCDS Trigger Set Select Register
  [11:8] OTGB1 — Trigger Set for OTGB1 - OTGB1
  [3:0] OTGB0 — Trigger Set for OTGB0 - OTGB0
0x1E4 OTSC0 32-bit — OCDS Trigger Set Control 0 Register
  [27:24] B1HAM — OTGB1 TS16_ADCMON High Byte - B1HAM
  [19:16] B1LAM — OTGB1 TS16_ADCMON Low Byte - B1LAM
  [11:8] B0HAM — OTGB0 TS16_ADCMON High Byte - B0HAM
  [3:0] B0LAM — OTGB0 TS16_ADCMON Low Byte - B0LAM
0x1E8 OTSC1 32-bit — OCDS Trigger Set Control 1 Register
  [31:24] SMCDBG — OTGB0 TS16_EVRCON SMCDBG - SMCDBG
  [23:16] DMONAD — OTGB0 TS16_EVRCON DMONAD - DMONAD
  [11:8] B1EC — OTGB1 TS16_EVRCON - B1EC
  [3:0] B0EC — OTGB0 TS16_EVRCON - B0EC
0x1F8 ACCEN1 32-bit ro — Access Enable Register 1
0x1FC ACCEN0 32-bit reset 0xFFFFFFFF — Access Enable Register 0
  [n] EN{n} (n=0..31) — Access Enable for Master TAG ID {n} - EN{n}
